# MIK32 register map
Vendor: Mikron JSC; Series: MIK32; File version: 1.0
Registers are 32-bit, read-write, reset 0x0 unless marked. A register's access mark holds for its fields unless they carry their own. Offsets are from the block's base; [hi:lo] are bit positions.

## BOOT_MANAGER — Блок управления режимом загрузки
Base 0x00060800
0x00 BOOT ro — Регистр режима загрузки
  [1:0] BOOT_MODE — Регистр чтения режима загрузки
    0=EEPROM (Старт из внутреннего ЭСППЗУ); 1=RAM (Старт из системного ОЗУ); 2=SPIFI (Старт из внешней памяти с использованием контроллера SPIFI)

## CRYPTO — Криптоблок
Base 0x00080000
0x00 BLOCK — Буфер данных для шифрования
0x04 KEY wo — Буфер данных ключа
0x08 INIT wo — Буфер данных вектора инициализации
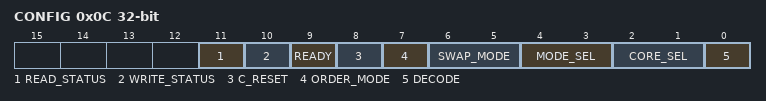
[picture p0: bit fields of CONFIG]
0x0C CONFIG — Регистр конфигурации
  [11] READ_STATUS ro — Буфер данных доступен для чтения
    0=UNAVAILABLE (Недоступно); 1=AVAILABLE (Доступно)
  [10] WRITE_STATUS ro — Буфер данных доступен для записи
    0=UNAVAILABLE (Недоступно); 1=AVAILABLE (Доступно)
  [9] READY ro — Состояние доступности модуля
    0=BUSY (Занято); 1=AVAILABLE (Доступно)
  [8] C_RESET — Сброс счётчиков загружаемых/выгружаемых данных
  [7] ORDER_MODE — Выбор порядка загрузки/выгрузки
    0=LSW (От младшего слова к старшему); 1=MSW (От старшего слова к младшему)
  [6:5] SWAP_MODE — Регистр выбора режима перестановки слова
    0=NONE (Нет перестановки); 1=HALF_WORD (Перестановка по полуслову); 2=BYTE (Перестановки по байтам); 3=BIT (Перестановка по битам)
  [4:3] MODE_SEL — Регистр выбора режима шифрования
    0=ECB (Режиме простой замены (ECB)); 1=CBC (Режим сцепления блоков (CBC)); 2=CTR (Режим гаммирования (CTR))
  [2:1] CORE_SEL — Регистр выбора алгоритма шифрования
    0=KUZNECHIK («Кузнечик»); 1=MAGMA («Магма»); 2=AES
  [0] DECODE — Задаёт режим хода вычислительного ядра
    0=ENCODE (Прямой ход (шифрование)); 1=DECODE (Обратный ход (расшифровка))

## CRC — Блок вычисления контрольных сумм
Base 0x00080400
0x00 DATA — Регистр данных
0x04 POLY — Регистр полинома
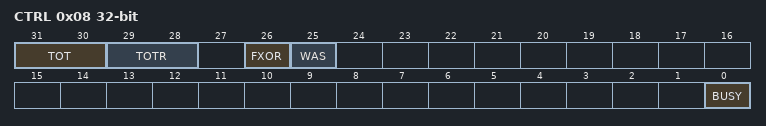
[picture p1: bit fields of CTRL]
0x08 CTRL — Регистр управления
  [31:30] TOT — Перестановка битов/байтов входных данных
    0=NONE (Перестановка выключена); 1=BITS (Биты в байтах перестанавливаются (бит 7 с битом 0, бит 15 с битом 8, с остальными байтами так же), байты НЕ перестанавливаются;); 2=BITS_BYTES (Перестанавливаются и биты, и байты); 3=BYTES (Биты в байтах НЕ перестанавливаются, байты перестанавливаются (меняются местами байты 3 и 0, 2 и 1);)
  [29:28] TOTR — Перестановки битов/байтов выходных данных
    0=NONE (Перестановка выключена); 1=BITS (Биты в байтах перестанавливаются (бит 7 с битом 0, бит 6 с битом 1 и т.д.; бит 15 c битом 8, бит 14 с битом 9 и т.д., с остальными байтами так же), байты НЕ перестанавливаются); 2=BITS_BYTES (Перестанавливаются и биты, и байты); 3=BYTES (Биты в байтах НЕ перестанавливаются, байты перестанавливаются (меняются местами байты 3 и 0, 2 и 1);)
  [26] FXOR — Инверсия контрольной суммы. Некоторые протоколы подсчёта контрольной суммы требуют инверсии вычисленного значения контрольной суммы (выполняется операция XOR со значением 0xFFFFFFFF)
    0=INVERSION_DISABLE (Инверсия выключена); 1=INVERSION_ENABLE (Инверсия включена (операция XOR выполняется))
  [25] WAS — Назначение регистра данных
    0=DATA (Записываем данные); 1=INIT_DATA (Записываем начальное значение)
  [0] BUSY ro — Бит занятости автомата. После записи в регистр данных слова для вычисления контрольной суммы бит занятости перейдет в состояние единицы через один такт после такта записи. То есть чтение регистра управления, идущее на шине AHB сразу на следующем такте после записи данных, вернет результат с нулевым (еще не обновленным) значением бита Busy
    0=READY (Автомат закончил вычисления); 1=BUSY (Автомат занят)

## WDT — Сторожевой таймер
Base 0x00081000
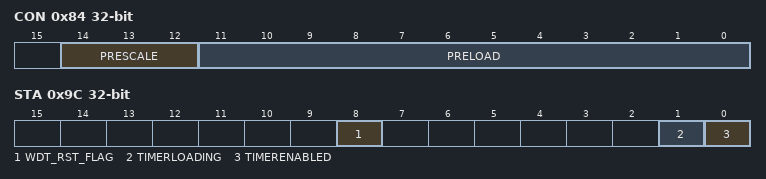
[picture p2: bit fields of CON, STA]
0x84 CON — Конфигурация
  [14:12] PRESCALE — Делитель входной частоты (Fclk) для таймера
    0=Fclk / 1; 1=Fclk / 2; 2=Fclk / 4; 3=Fclk / 16; 4=Fclk / 64; 5=Fclk / 256; 6=Fclk / 1024; 7=Fclk / 4096
  [11:0] PRELOAD — Начальное значение таймера при запуске или перезапуске (таймер считает в сторону увеличения значений)
0x9C KEY wo — Регистр ключа
0x9C STA ro — Регистр состояния
  [8] WDT_RST_FLAG — Флаг генерации сброса сторожевым таймером. Сбрасывается в 0 только при снятии и последующей подаче питания
  [1] TIMERLOADING — Бит перезагрузки значения
    0=Reloading_complete (Перезагрузка значения таймера в данный момент не выполняется (завершена)); 1=Reloading (Выполняется перезагрузка значения в таймере)
  [0] TIMERENABLED — Бит активности таймера
    0=Disable (Таймер остановлен); 1=Enable (Таймер запущен)

## Notices in the file
MIT License
Copyright (C) 2024 Лаборатория системных разработок, Mikron JSC
Permission is hereby granted, free of charge, to any person obtaining a copy
of this software and associated documentation files (the «Software»), to deal
in the Software without restriction, including without limitation the rights
to use, copy, modify, merge, publish, distribute, sublicense, and/or sell
copies of the Software, and to permit persons to whom the Software is
furnished to do so, subject to the following conditions:
The above copyright notice and this permission notice shall be included in all
copies or substantial portions of the Software.
THE SOFTWARE IS PROVIDED «AS IS», WITHOUT WARRANTY OF ANY KIND, EXPRESS OR
IMPLIED, INCLUDING BUT NOT LIMITED TO THE WARRANTIES OF MERCHANTABILITY,
FITNESS FOR A PARTICULAR PURPOSE AND NONINFRINGEMENT. IN NO EVENT SHALL THE
AUTHORS OR COPYRIGHT HOLDERS BE LIABLE FOR ANY CLAIM, DAMAGES OR OTHER
LIABILITY, WHETHER IN AN ACTION OF CONTRACT, TORT OR OTHERWISE, ARISING FROM,
OUT OF OR IN CONNECTION WITH THE SOFTWARE OR THE USE OR OTHER DEALINGS IN THE
SOFTWARE
